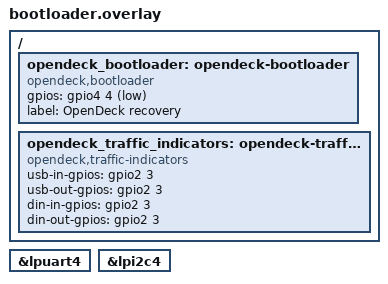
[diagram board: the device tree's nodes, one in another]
opendeck_uart_din_midi: &lpuart4 {};       /* Teensy pins 8 (TX4) / 7 (RX4) */

opendeck_uart_touchscreen: &lpuart4 {};    /* Teensy pins 8 (TX4) / 7 (RX4) */

opendeck_i2c_display: &lpi2c4 {};          /* Teensy pins 24 (SCL2) / 25 (SDA2) */

/ {
    opendeck_bootloader: opendeck-bootloader {
        compatible = "opendeck,bootloader";
        gpios = <&gpio4 4 (GPIO_PULL_UP | GPIO_ACTIVE_LOW)>;
        label = "OpenDeck recovery";
    };

    opendeck_traffic_indicators: opendeck-traffic-indicators {
        compatible = "opendeck,traffic-indicators";
        usb-in-gpios = <&gpio2 3 GPIO_ACTIVE_HIGH>;
        usb-out-gpios = <&gpio2 3 GPIO_ACTIVE_HIGH>;
        din-in-gpios = <&gpio2 3 GPIO_ACTIVE_HIGH>;
        din-out-gpios = <&gpio2 3 GPIO_ACTIVE_HIGH>;
    };
};
